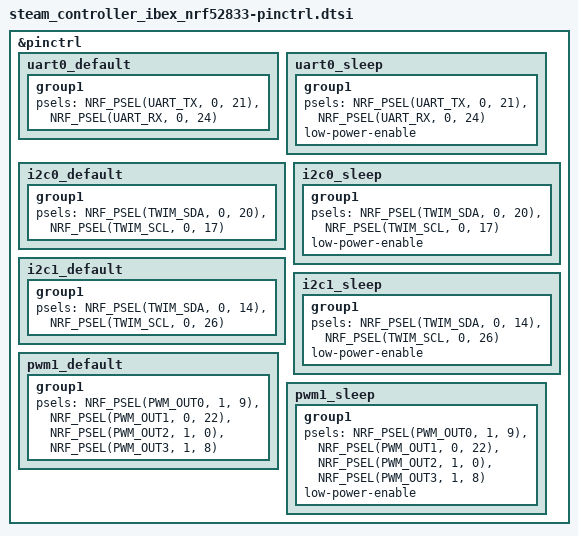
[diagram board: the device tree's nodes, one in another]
/* SPDX-License-Identifier: AGPL-3.0-or-later */

#include <zephyr/dt-bindings/pinctrl/nrf-pinctrl.h>

&pinctrl {
	uart0_default: uart0_default {
		group1 {
			psels = <NRF_PSEL(UART_TX, 0, 21)>,
				<NRF_PSEL(UART_RX, 0, 24)>;
		};
	};

	uart0_sleep: uart0_sleep {
		group1 {
			psels = <NRF_PSEL(UART_TX, 0, 21)>,
				<NRF_PSEL(UART_RX, 0, 24)>;
			low-power-enable;
		};
	};

	i2c0_default: i2c0_default {
		group1 {
			psels = <NRF_PSEL(TWIM_SDA, 0, 20)>,
				<NRF_PSEL(TWIM_SCL, 0, 17)>;
		};
	};

	i2c0_sleep: i2c0_sleep {
		group1 {
			psels = <NRF_PSEL(TWIM_SDA, 0, 20)>,
				<NRF_PSEL(TWIM_SCL, 0, 17)>;
			low-power-enable;
		};
	};

	i2c1_default: i2c1_default {
		group1 {
			psels = <NRF_PSEL(TWIM_SDA, 0, 14)>,
				<NRF_PSEL(TWIM_SCL, 0, 26)>;
		};
	};

	i2c1_sleep: i2c1_sleep {
		group1 {
			psels = <NRF_PSEL(TWIM_SDA, 0, 14)>,
				<NRF_PSEL(TWIM_SCL, 0, 26)>;
			low-power-enable;
		};
	};

	pwm1_default: pwm1_default {
		group1 {
			psels = <NRF_PSEL(PWM_OUT0, 1, 9)>,
				<NRF_PSEL(PWM_OUT1, 0, 22)>,
				<NRF_PSEL(PWM_OUT2, 1, 0)>,
				<NRF_PSEL(PWM_OUT3, 1, 8)>;
		};
	};

	pwm1_sleep: pwm1_sleep {
		group1 {
			psels = <NRF_PSEL(PWM_OUT0, 1, 9)>,
				<NRF_PSEL(PWM_OUT1, 0, 22)>,
				<NRF_PSEL(PWM_OUT2, 1, 0)>,
				<NRF_PSEL(PWM_OUT3, 1, 8)>;
			low-power-enable;
		};
	};
};
